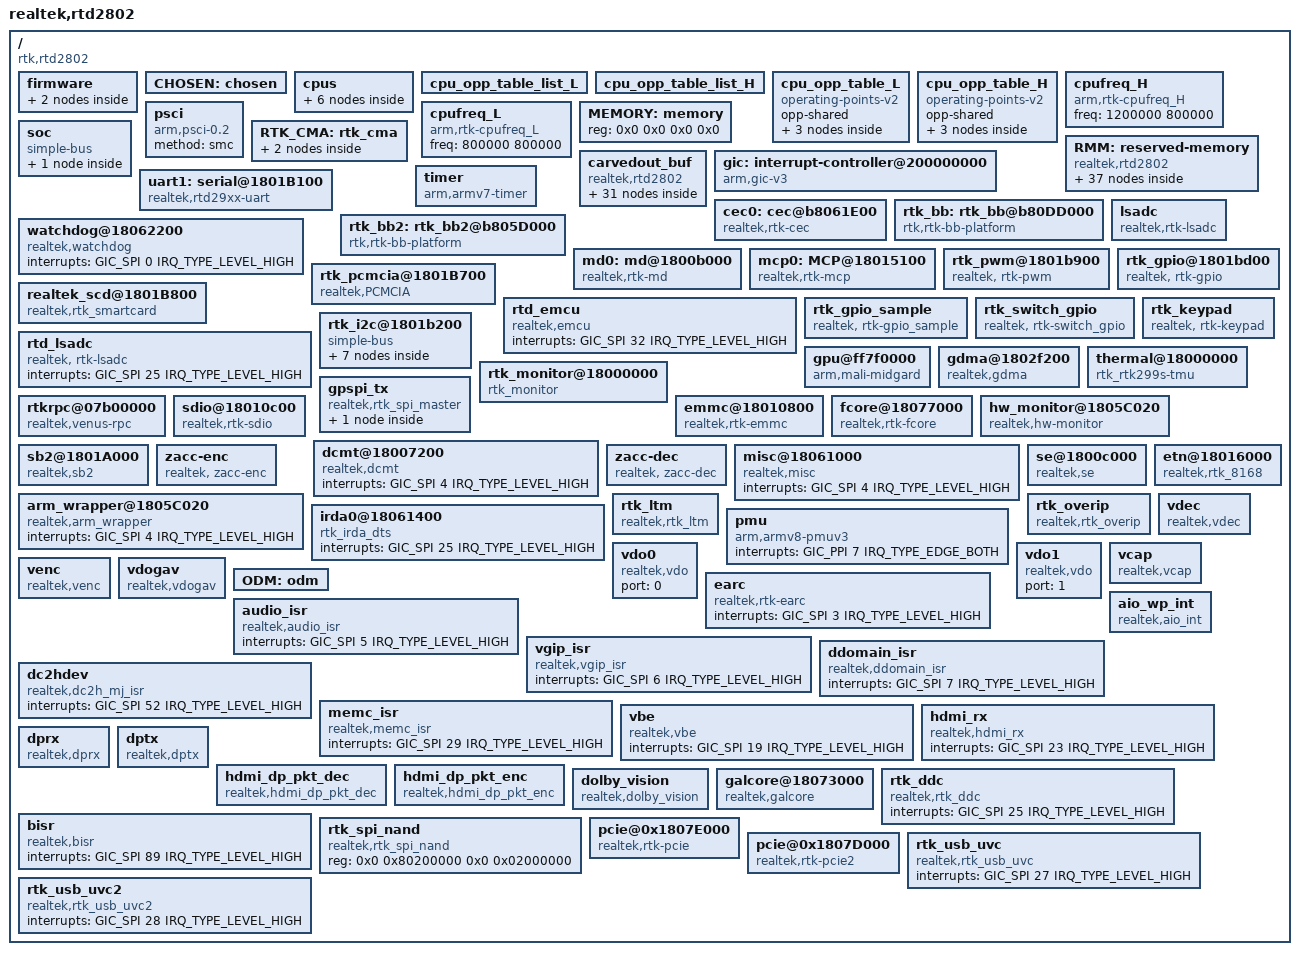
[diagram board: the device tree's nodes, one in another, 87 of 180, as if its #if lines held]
/*
 * rtd2802 device tree source
 *
*/

#include <dt-bindings/interrupt-controller/irq.h>
#include <dt-bindings/interrupt-controller/arm-gic.h>

#include <rtk-dt-binding_chip/rtk_kdriver/rmm/rmm_carvedout.h>
#include <rtk-dt-binding_linux/generated/autoconf.h>
#include <rtk-dt-binding_linux/generated/uapi/linux/version.h>

/dts-v1/;
/include/ "skeleton.dtsi"
#include "rtk_usb_2802.dtsi"
/include/ "rtd2802_otp_table.dtsi"

#define _KB_ 1024
#define _MB_ 1024*1024

/* define cma1 from end to specified size ahead, and boottime borrowed regions */
#define _CMA_LO_SIZE_       ( 32 * _MB_)
#define _CMA_LO_END_        (0x07000000)
#define _CMA_LO_START_      (_CMA_LO_END_ - _CMA_LO_SIZE_)  // cma1 region

#ifdef CONFIG_REALTEK_MEMORY_MANAGEMENT_MODULE
/* for legacy reclaim & last it takes 64+8MB, but referring bootcode it takes 39+N (N for boot logo)
    the boot logo reserved-memory which will be reclaimed should starts from _CMA_LKOGO_ANIM_,
    enough for raw/jpeg logo, no overlap during kernel boot and before android logo */
#define _CMA_LOGO_ANIM_     (0x03800000 + 0   *_MB_)        // anim
#define _CMA_LOGO_PIC_      (0x03800000 + 64  *_MB_)        // pic
#else
#define _CMA_LOGO_ANIM_     (_CMA_LO_START_ + 0   *_MB_)    // anim
#define _CMA_LOGO_PIC_      (_CMA_LO_START_ + 64  *_MB_)    // pic
#endif


/ {
	model = "realtek,rtd2802";
	compatible = "rtk,rtd2802";
	interrupt-parent = <&gic>;
	#address-cells = <2>;
	#size-cells = <2>;

	firmware {
		android {
			compatible = "android,firmware";
			hardware = "rtd2802";
		};
	};

	CHOSEN: chosen {
#if defined(CONFIG_GKI_HACKS_TO_FIX) && defined(CONFIG_RTK_KDRV_SERIAL_8250_MODULE)
		bootargs = "earlycon cgroup.memory=nokmem firmware_class.path=/vendor/firmware androidboot.console=ttyRTK1 console=ttyRTK1,115200";
#else
		bootargs = "earlycon cgroup.memory=nokmem firmware_class.path=/vendor/firmware";
#endif
		stdout-path = &uart1;
	};

	cpus {
		#address-cells = <0x1>;
		#size-cells = <0>;

		cpu-map {
			cluster0: cluster0 {
				#cooling-cells = <2>; /* min followed by max */

				core0 {
					cpu = <&A73_0>;
				};
				core1 {
					cpu = <&A73_1>;
				};
			};
		};

		A73_0: cpu@0 {
			compatible = "arm,cortex-a73","arm,armv8";
			reg = <0x0>;
			device_type = "cpu";
			enable-method = "psci";
			clock-names = "vlittle";
			operating-points-v2 = <&cpu_opp_table_L>;
			capacity-dmips-mhz = <729>;
			dynamic-power-coefficient = <512>;
		};
		A73_1: cpu@1 {
			compatible = "arm,cortex-a73","arm,armv8";
			reg = <0x1>;
			device_type = "cpu";
			enable-method = "psci";
			clock-names = "vlittle";
			operating-points-v2 = <&cpu_opp_table_L>;
			capacity-dmips-mhz = <729>;
			dynamic-power-coefficient = <512>;
		};
	};

	cpu_opp_table_list_L {
		operating-points-0 = <&cpu_opp_table_L>;
		operating-points-1 = <&cpu_opp_table_L>;
	};

	cpu_opp_table_list_H {
		operating-points-0 = <&cpu_opp_table_H>;
		operating-points-1 = <&cpu_opp_table_H>;
	};

	cpu_opp_table_L: cpu_opp_table_L {
		compatible = "operating-points-v2";
		opp-shared;

		opp-1 {
			opp-hz = /bits/ 64 <799000000>;
			opp-microvolt = <890000>;
			opp-level = <1>;
		};
		opp-2 {
			opp-hz = /bits/ 64 <800000000>;
			opp-microvolt = <890000>;
			opp-level = <1>;
		};
		opp-3 {
			opp-hz = /bits/ 64 <880000000>;
			opp-microvolt = <890000>;
			opp-level = <1>;
		};
	};

	cpu_opp_table_H: cpu_opp_table_H {
		compatible = "operating-points-v2";
		opp-shared;

		opp-1 {
			opp-hz = /bits/ 64 <800000000>;
			opp-microvolt = <890000>;
			opp-level = <1>;
		};
		opp-2 {
			opp-hz = /bits/ 64 <1200000000>;
			opp-microvolt = <890000>;
			opp-level = <1>;
		};
		opp-3 {
			opp-hz = /bits/ 64 <1320000000>;
			opp-microvolt = <890000>;
			opp-level = <1>;
		};
	};

	cpufreq_H {
		compatible = "arm,rtk-cpufreq_H";
		freq = <1200000 800000>;
	};

	cpufreq_L {
		compatible = "arm,rtk-cpufreq_L";
		freq = <800000 800000>;
	};

	psci {
		compatible  = "arm,psci-0.2";
		method = "smc";
	};

	MEMORY:memory {
		device_type = "memory";
		reg = <0x0 0x0 0x0 0x0>;
	};

	RMM: reserved-memory {
		#address-cells = <2>;
		#size-cells = <2>;
		ranges;

		//! Default REF platform memory layout dts
		//!  there will be other concatenated dtb and overlay dto for different board variants
		compatible = "realtek,rtd2802";

		boot: boot_memory {                 reg = <0x0 0x00000000 0x0 (1536 *_KB_)>;
		};

		dmem: dmem_memory {                 reg = <0x0 0x10000000 0x0 (0    *_MB_)>;
			status = "disabled";
			/* BAN_NORMAL if size */
		};

		comem: comem_memory {               reg = <0x0 0x10000000 0x0 (0    *_MB_)>;
			status = "disabled";
		};

		audio: audio_memory {               reg = <0x0 0x14000000 0x0 (0   *_MB_)>;
			no-map;
			status = "disabled";
		};

		demod: demod_memory {               reg = <0x0 0x15400000 0x0 (0    *_MB_)>;
			/* BAN_NOT_USED */
			status = "disabled";
		};

		kboot: kboot_memory {               reg = <0x0 0x15f00000 0x0 (0    *_MB_)>;
			status = "disabled"; // it's 0 at rmm.c
		};

		kcpu: kcpu_memory {                 reg = <0x0 0x07a80000 0x0 (512   *_KB_)>;
			no-map;
			/* BAN_NOT_USED if ! OPTEE */
		};

		gic_mem: gic_mem {                  reg = <0x0 0x17c00000 0x0 (0    *_MB_)>; // HW FIXED
			no-map;
			status = "disabled";
		};

		rbus: rbus_memory {                 reg = <0x0 0x18000000 0x0 (2    *_MB_)>; // HW FIXED
			no-map;
		};


		wov: wov_memory {                        reg = <0x0 0x1a500000 0x0 (0    *_MB_)>;
			status = "disabled";
		};

		emcu: emcu_memory {                       reg = <0x0 0x07180000 0x0 (3    *_MB_)>;
			no-map;
		};

		vcpu: vcpu_memory {                 reg = <0x0 0x07480000 0x0 (6    *_MB_)>;
			no-map;
		};

		rpc: rpc_memory {                   reg = <0x0 0x07b00000 0x0 (1020  *_KB_)>;
		};

		acpu: acpu_memory {                 reg = <0x0 0x1b200000 0x0 (0   *_MB_)>;
			no-map;
			status = "disabled";
		};

		/*
		 * The maximum reserved space for logbuf
		 *  bootloader can specify smaller size (e.g. 512K) and update loaded fdt to free unused.
		 */
		logbuf: logbuf_memory {             reg = <0x0 0x07c00000 0x0 (4    *_MB_)>;

			/* rtdlog_get_buffer_size() should be early in kernel */
		};

		rom: rom_memory {                   reg = <0x0 0xffff0000 0x0 0x00010000>;
		};

		pstore: pstore_memory {             reg = <0x0 0x1fd00000 0x0 (0   *_KB_)>;
			status = "disabled";
		};

		irtbl: irtbl_memory {               reg = <0x0 0x07bff000 0x0 (4    *_KB_)>;
		};

		ddr_bd1: ddr_bd1_memory {           reg = <0x0 0x0 0x0 0x0>;
			status = "disabled";
			no-map;
			/* BAN_NOT_USED if ddr_swap */
		};
		ddr_bd2: ddr_bd2_memory {           reg = <0x0 0x0 0x0 0x0>;
			status = "disabled";
			/* BAN_NOT_USED if size */
		};

		// CARVEDOUT_VDEC_VBM
		// (paired with ...CARVEOUT_HEAP_CHUNK_SIZE)
		vdec_vbm: vdec-vbm_memory {         reg = <0x0 0x0 0x0 0x0>;
			no-map; // VDEC_VBM(remove), CMA_VBM(reserve)
			status = "disabled";
		};

		// CARVEDOUT_CMA_VBM
		// (paired with VBM_HEAP_...CHUNK_SIZE)
		vbm: cma-vbm_memory {               reg = <0x0 0x20000000 0x0 (224  *_MB_)>;
			/* no-map; */ // VDEC_VBM(remove), CMA_VBM(reserve)

			// CARVEDOUT_CMA_VBM
			//! 1. should be shared-dma_pool for native reserve-memory to reserve it for dma/cma
			//! 2. 'xxxx'_memory should be paired with rtkcma_list[ ] name in auth
			compatible = "shared-dma-pool"; // CMA_VBM(reserve)
			reusable;
			status = "disabled";
		};

		scaler_memc: scaler_memc {          reg = <0x0 0x2e000000 0x0 (0   *_MB_)>;
			no-map;
			status = "disabled";
		};

		scaler_mdomain: scaler_mdomain {    reg = <0x0 0x33c00000 0x0 (0   *_MB_)>;
			no-map;
			status = "disabled";
		};

		scaler_dinr: scaler_dinr {          reg = <0x0 0x35800000 0x0 (0   *_MB_)>;
			no-map;
			status = "disabled";
		};

		scaler_vip: scaler_vip {            reg = <0x0 0x36200000 0x0 (0    *_MB_)>;
			no-map;
			status = "disabled";
		};

		scaler_od: scaler_od {              reg = <0x0 0x36500000 0x0 (0    *_MB_)>;
			no-map;
			status = "disabled";
		};

		scaler_nn: scaler_nn {              reg = <0x0 0x36e00000 0x0 (0    *_MB_)>;
			no-map;
			status = "disabled";
		};
		scaler_align: _scaler_align {       reg = <0x0 0x36f00000 0x0 (0    *_MB_)>; // ??? scaler reserve 4MB-aligned ???
		};

		tp: tp_memory {                     reg = <0x0 0x37000000 0x0 (0   *_MB_)>;
			//no-map;
			status = "disabled";
		};

		// CARVEDOUT_GPU_RESERVED


		// CARVEDOUT_VDEC_RINGBUF
		svp: svp_memory {                   reg = <0x0 0x3f000000 0x0 (0   *_MB_)>;
			no-map;
			status = "disabled";
		};

		// CARVEDOUT_CMA_LOW

		cma1: cma1_memory {                 reg = <0x0 _CMA_LO_START_ 0x0 _CMA_LO_SIZE_>;
			compatible = "shared-dma-pool";
			reusable;
#ifndef CONFIG_REALTEK_MEMORY_MANAGEMENT_MODULE
			linux,cma-default;
#endif
		};

		// CARVEDOUT_CMA_HIGH
		// CARVEDOUT_CMA_GPU_4K
		/*
		 * carvedout_buf_query[ CARVEDOUT_GPU_RESERVED ]
		 *  (layout_idx == MM_LAYOUT_DEFAULT)  CMA_HIGHMEM_TV_4K; //688MB
		 *  (layout_idx == MM_LAYOUT_DIAS_2GB)  CMA_HIGHMEM_DIAS_2GB; //704MB
		 *
		 *  tp_memory end 0x37000000
		 *  dram      end 0x80000000 : 0x20000000+0x60000000
		 *
		 *  0x37000000 + 128MB(ZRAM_RESERVED_SIZE) + 688MB(CMA_HIGHMEM_TV_4K)
		 *  = 0x37000000 + 0x08000000 + 0x2b000000 = 0x6a000000
		 *
		 *  0x80000000 - 0x6a000000 = 0x16000000 = 352*_MB_
		 */

		/*
		 * if carvedout start < CARVEDOUT_LIMIT(512MB), then NO cma2
		 */

		/*
		 * if UI_4K, CMA_GPU_4K use an exclusive region from original CMA2
		 */

		cma_ui4k: cma-ui4k_memory {         reg = <0x0 0x0 0x0 0x0>;
			compatible = "shared-dma-pool";
			reusable;
			status = "disabled";
		};
		cma2: cma2_memory {                 reg = <0x0 0x0c000000 0x0 ( 64 *_MB_)>;
			compatible = "shared-dma-pool";
			reusable;
		};

		// CARVEDOUT_CMA_3
		cma3_memory {                       reg = <0x0 0x0c000000 0x0 ( 0   *_MB_)>;
			compatible = "shared-dma-pool";
			reusable;
			status = "disabled";
		};
		
		// CARVEDOUT_CMA_LOW_LIMIT
		// CARVEDOUT_CMA_BW

		spi_iomem {                         reg = <0x0 0x80200000 0x0 0x02000000>; // HW FIXED
			no-map;
		};

		// for those less than 4G, prevent them touching 4G addr space
		// especially for those like fixed 2G rescue, or hacked 2G
		reserved_4g {                       reg = <0x0 0xC0000000 0x0 0x40000000>;
			no-map;
		};

	};


	//[TODO] for GKI, cma1 region is reserved in the very beginning but will be returned back to buddy after init.
	//         reserve_dvr_memory() may not be loaded and reserves it in time to avoid other driver access.
	//         may need to be more careful on module loading order.

	/*
	 * CMA param
	 */
	RTK_CMA: rtk_cma {
		#address-cells = <2>;
		#size-cells = <2>;

		reclaim_memory {                    reg = <0x0 _CMA_LOGO_ANIM_ 0x0 (64   *_MB_)>;
		};

		last_image_memory {                 reg = <0x0 _CMA_LOGO_PIC_  0x0 (8    *_MB_)>;
		};
	};

	carvedout_buf {
		#address-cells = <1>;
		#size-cells = <0>;

		compatible = "realtek,rtd2802";
		memory-region = <&MEMORY>;

		/* carvedout idx, refer rmm.h */

		bufnum = < CARVEDOUT_NUM >;

		@CARVEDOUT_BOOTCODE {
			memory-region = "boot_memory";
			reg = < CARVEDOUT_BOOTCODE >;
		};
		@CARVEDOUT_DEMOD {
			memory-region = "demod_memory";
			reg = < CARVEDOUT_DEMOD >;
		};
		@CARVEDOUT_AV_DMEM {
			memory-region = "dmem_memory";
			reg = < CARVEDOUT_AV_DMEM >;
		};
//		@CARVEDOUT_VDEC_COMEM {
//			memory-region = "comem_memory";
//			reg = < CARVEDOUT_VDEC_COMEM >;
//		};
		@CARVEDOUT_AUDIO {
			memory-region = "audio_memory";
			reg = < CARVEDOUT_AUDIO >;
		};
		@CARVEDOUT_K_BOOT {
			memory-region = "kboot_memory";
			reg = < CARVEDOUT_K_BOOT >;
		};
		@CARVEDOUT_K_OS {
			memory-region = "kcpu_memory";
			reg = < CARVEDOUT_K_OS >;
		};
		@CARVEDOUT_MAP_GIC {
			memory-region = "gic_mem";
			reg = < CARVEDOUT_MAP_GIC >;
		};
		@CARVEDOUT_MAP_RBUS {
			memory-region = "rbus_memory";
			reg = < CARVEDOUT_MAP_RBUS >;
		};
		//CARVEDOUT_GPU_FW {
		//};
		@CARVEDOUT_V_OS {
			memory-region = "vcpu_memory";
			reg = < CARVEDOUT_V_OS >;
		};
		@CARVEDOUT_MAP_RPC {
			memory-region = "rpc_memory";
			reg = < CARVEDOUT_MAP_RPC >;
		};
		@CARVEDOUT_A_OS {
			memory-region = "acpu_memory";
			reg = < CARVEDOUT_A_OS >;
		};
		@CARVEDOUT_LOGBUF {
			memory-region = "logbuf_memory";
			reg = < CARVEDOUT_LOGBUF >;
		};
		@CARVEDOUT_ROMCODE {
			memory-region = "rom_memory";
			reg = < CARVEDOUT_ROMCODE >;
		};
		@CARVEDOUT_RAMOOPS {
			memory-region = "pstore_memory";
			reg = < CARVEDOUT_RAMOOPS >;
		};
		@CARVEDOUT_IR_TABLE {
			memory-region = "irtbl_memory";
			reg = < CARVEDOUT_IR_TABLE >;
		};

		@CARVEDOUT_DDR_BOUNDARY {
			memory-region = "ddr_bd1_memory";
			reg = < CARVEDOUT_DDR_BOUNDARY >;
		};
		@CARVEDOUT_DDR_BOUNDARY_2 {
			memory-region = "ddr_bd2_memory";
			reg = < CARVEDOUT_DDR_BOUNDARY_2 >;
		};

		@CARVEDOUT_VDEC_RINGBUF {
			memory-region = "svp_memory";
			reg = < CARVEDOUT_VDEC_RINGBUF >;
		};

		//CARVEDOUT_SCALER

		@CARVEDOUT_SCALER_MEMC {
			memory-region = "scaler_memc";
			reg = < CARVEDOUT_SCALER_MEMC >;
		};
		@CARVEDOUT_SCALER_MDOMAIN {
			memory-region = "scaler_mdomain";
			reg = < CARVEDOUT_SCALER_MDOMAIN >;
		};
		@CARVEDOUT_SCALER_DI_NR {
			memory-region = "scaler_dinr";
			reg = < CARVEDOUT_SCALER_DI_NR >;
		};
		@CARVEDOUT_SCALER_NN {
			memory-region = "scaler_nn";
			reg = < CARVEDOUT_SCALER_NN >;
		};
		@CARVEDOUT_SCALER_VIP {
			memory-region = "scaler_vip";
			reg = < CARVEDOUT_SCALER_VIP >;
		};
		@CARVEDOUT_SCALER_OD {
			memory-region = "scaler_od";
			reg = < CARVEDOUT_SCALER_OD >;
		};

		@CARVEDOUT_VDEC_VBM {
			memory-region = "vdec-vbm_memory";
			reg = < CARVEDOUT_VDEC_VBM>;
		};

		@CARVEDOUT_CMA_VBM {
			memory-region = "cma-vbm_memory";
			reg = < CARVEDOUT_CMA_VBM >;
		};

			@CARVEDOUT_TP {
			memory-region = "tp_memory";
			reg = < CARVEDOUT_TP >;
		};

		@CARVEDOUT_CMA_LOW {
			memory-region = "cma1_memory";
			reg = < CARVEDOUT_CMA_LOW >;
		};

		@CARVEDOUT_CMA_HIGH {
			memory-region = "cma2_memory";
			reg = < CARVEDOUT_CMA_HIGH >;
		};

		@CARVEDOUT_CMA_GPU_4K {
			memory-region = "cma-ui4k_memory";
			reg = < CARVEDOUT_CMA_GPU_4K >;
		};

		@CARVEDOUT_CMA_3 {
			memory-region = "cma3_memory";
			reg = < CARVEDOUT_CMA_3 >;
		};
	};


	firmware {
		optee {
			compatible = "linaro,optee-tz";
			method = "smc";
		};
	};

	gic:interrupt-controller@200000000 {
		compatible = "arm,gic-v3";
		#interrupt-cells = <0x3>;
		#address-cells = <0x2>;
		#size-cells = <0x2>;
		interrupt-controller;
		redistributor-stride = <0x0 0x20000>;
		#redistributor-regions = <1>;
		reg = <0x2 0x00000000 0x0 0x10000>,	   // GICD
				<0x2 0x00040000 0x0 0x200000>;	  // GICR
		interrupts = <GIC_PPI 9 (GIC_CPU_MASK_SIMPLE(4) | IRQ_TYPE_LEVEL_LOW)>;
	};

	soc {
		compatible = "simple-bus";
		#address-cells = <1>;
		#size-cells = <1>;
		ranges = <0 0 0 0xffffffff>; // 32bit addressing

		reg_bus: common@18000000 {
			compatible = "realtek,common";
			#address-cells = <1>;
			#size-cells = <1>;
			reg = <0x18000000 0x200000>;
			ranges = <0 0x18000000 0x200000>;
#if 0
			my_driver: syscon@0 {
				compatible = "syscon", "simple-mfd";
			};
#endif
		};
	};

	timer {
		compatible = "arm,armv7-timer";
		interrupts =
			<GIC_PPI 13 (GIC_CPU_MASK_SIMPLE(4) | IRQ_TYPE_LEVEL_LOW)>,
			<GIC_PPI 14 (GIC_CPU_MASK_SIMPLE(4) | IRQ_TYPE_LEVEL_LOW)>,
			<GIC_PPI 11 (GIC_CPU_MASK_SIMPLE(4) | IRQ_TYPE_LEVEL_LOW)>,
			<GIC_PPI 10 (GIC_CPU_MASK_SIMPLE(4) | IRQ_TYPE_LEVEL_LOW)>;
		clock-frequency = <27000000>;
		always-on = "true";
		arm,no-tick-in-suspend;
	};

	uart1: serial@1801B100 {
		#address-cells = <2>;
		size-cells = <2>;
		compatible = "realtek,rtd29xx-uart", "ns16550";
		reg-shift = <2>;
		reg-io-width = <4>;
		reg = <0x00000000 0x1801B100 0x00000000 0x1000>;
		interrupts = <GIC_SPI 19 IRQ_TYPE_LEVEL_HIGH>,
					<GIC_SPI 17 IRQ_TYPE_LEVEL_HIGH>,
					<GIC_SPI 17 IRQ_TYPE_LEVEL_HIGH>,
					<GIC_SPI 17 IRQ_TYPE_LEVEL_HIGH>;
	};

	cec0: cec@b8061E00 {
		compatible = "realtek,rtk-cec";
		reg = <0x00000000 0x18061E00 0x00000000 0x1000>;
		interrupts = <GIC_SPI 25 IRQ_TYPE_LEVEL_HIGH>;
	};

	rtk_bb: rtk_bb@b80DD000 {
		compatible = "rtk,rtk-bb-platform";
		reg = <0x00000000 0x180DD000 0x00000000 0x1000>;
		interrupts = <GIC_SPI 46 IRQ_TYPE_LEVEL_HIGH>;
		id = <0x0>;
	};

	rtk_bb2: rtk_bb2@b805D000 {
		compatible = "rtk,rtk-bb-platform";
		reg = <0x00000000 0x1807A000 0x00000000 0x1000>;
		interrupts = <GIC_SPI 46 IRQ_TYPE_LEVEL_HIGH>;
		id = <0x1>;
	};

	lsadc {
		compatible = "realtek,rtk-lsadc";
		reg = <0x00000000 0x18061500 0x00000000 0x100>;
		interrupts = <GIC_SPI 25 IRQ_TYPE_LEVEL_HIGH>;
	};

	watchdog@18062200 {
		compatible = "realtek,watchdog";
		interrupts = <GIC_SPI 0 IRQ_TYPE_LEVEL_HIGH>;
	};

	md0:md@1800b000 {
		compatible = "realtek,rtk-md";
		reg = <0x00000000 0x1800b000 0x00000000 0x230>;
		interrupts = <GIC_SPI 13 IRQ_TYPE_LEVEL_HIGH>;
	};

	mcp0:MCP@18015100 {
		compatible = "realtek,rtk-mcp";
		reg = <0x00000000 0x18015100 0x00000000 0x1000>;
		interrupts = <GIC_SPI 12 IRQ_TYPE_LEVEL_HIGH>;
	};


	rtk_pwm@1801b900 {
		compatible = "realtek, rtk-pwm";
		reg = <0x00000000 0x1801b900 0x00000000 0x194>, //misc pwm
				<0x00000000 0x18061280 0x00000000 0x34>;  //iso pwm
		interrupts = <GIC_SPI 37 IRQ_TYPE_LEVEL_HIGH>;  //misc pwm int
	};

	rtk_pcmcia@1801B700 {
		compatible = "realtek,PCMCIA";
		reg = <0x00000000 0x1801B700 0x00000000 0x24>;
		interrupts = <GIC_SPI 19 IRQ_TYPE_LEVEL_HIGH>;//IRQ_TYPE_EDGE_BOTH
	};

	realtek_scd@1801B800 {
		compatible = "realtek,rtk_smartcard";
		reg = <0x00000000 0x1801B800 0x00000000 0x7C>;
		interrupts = <GIC_SPI 19 IRQ_TYPE_LEVEL_HIGH>;//IRQ_TYPE_EDGE_BOTH
	};

	rtd_emcu {
		compatible = "realtek,emcu";
		interrupts = <GIC_SPI 32 IRQ_TYPE_LEVEL_HIGH>;
	};

	rtk_gpio@1801bd00 {
		compatible = "realtek, rtk-gpio";
		reg = <0x00000000 0x1801bd00 0x00000000 0xc0>, //misc gpio
				<0x00000000 0x18061100 0x00000000 0x4c>;
		interrupts = <GIC_SPI 33 IRQ_TYPE_LEVEL_HIGH>,  //misc gpio int*/
				<GIC_SPI 25 IRQ_TYPE_LEVEL_HIGH>;  //iso gpio int*/
	};

	rtk_gpio_sample {
		compatible = "realtek, rtk-gpio_sample";
	};

	rtk_switch_gpio {
		compatible = "realtek, rtk-switch_gpio";
	};

	rtk_keypad {
		compatible = "realtek, rtk-keypad";
	};

	rtd_lsadc {
		compatible = "realtek, rtk-lsadc";
		interrupts = <GIC_SPI 25 IRQ_TYPE_LEVEL_HIGH>;
	};

	rtk_i2c@1801b200 {
		compatible = "simple-bus";
		reg = <0x00000000 0x1801b200 0x00000000 0x3fc>, //misc i2c
				<0x00000000 0x18062500 0x00000000 0x1fc>; //iso i2c
		i2c0{
			compatible = "realtek, rtk-i2c";
			interrupts = <GIC_SPI 25 IRQ_TYPE_LEVEL_HIGH>; //iso misc irq
			pcb_info = <0 0 0 0>;	//logical_id:0, i2c_mode:0.hw_i2c	phy_id, src
						//							1.gpio_i2c sda,	scl
		};
		i2c1{
			compatible = "realtek, rtk-i2c";
			interrupts = <GIC_SPI 19 IRQ_TYPE_LEVEL_HIGH>; //misc irq
			pcb_info = <1 0 1 0>;	//logical_id:1, i2c_mode:0.hw_i2c	phy_id, src
						//							1.gpio_i2c sda,	scl
		};
		i2c2{
			compatible = "realtek, rtk-i2c";
			interrupts = <GIC_SPI 19 IRQ_TYPE_LEVEL_HIGH>; //misc irq
			pcb_info = <2 0 2 0>;	//logical_id2:, i2c_mode:0.hw_i2c	phy_id, src
						//							1.gpio_i2c sda,	scl
		};
		i2c3{
			compatible = "realtek, rtk-i2c";
			interrupts = <GIC_SPI 19 IRQ_TYPE_LEVEL_HIGH>; //misc irq
			pcb_info = <3 0 3 0>;   //logical_id2:, i2c_mode:0.hw_i2c   phy_id, src
						//                          1.gpio_i2c sda, scl
		};
		i2c4{
			compatible = "realtek, rtk-i2c";
			interrupts = <GIC_SPI 19 IRQ_TYPE_LEVEL_HIGH>; //misc irq
			pcb_info = <4 0 4 0>;   //logical_id2:, i2c_mode:0.hw_i2c   phy_id, src
						//                          1.gpio_i2c sda, scl
		};
		i2c5{
			compatible = "realtek, rtk-i2c";
			interrupts = <GIC_SPI 25 IRQ_TYPE_LEVEL_HIGH>; //iso misc irq
			pcb_info = <5 0 5 0>;   //logical_id2:, i2c_mode:0.hw_i2c   phy_id, src
						//                          1.gpio_i2c sda, scl
		};
		i2c6{
			compatible = "realtek, rtk-i2c";
			interrupts = <GIC_SPI 19 IRQ_TYPE_LEVEL_HIGH>; //misc irq
			pcb_info = <6 0 6 0>;   //logical_id2:, i2c_mode:0.hw_i2c   phy_id, src
						//                          1.gpio_i2c sda, scl
		};
	};

	gpu@ff7f0000{
		compatible = "arm,mali-midgard";
		reg = <0x00000000 0xff7f0000 0x00000000 0x4000>;
		interrupts = <GIC_SPI 44 IRQ_TYPE_LEVEL_HIGH>,
						<GIC_SPI 42 IRQ_TYPE_LEVEL_HIGH>,
						<GIC_SPI 14 IRQ_TYPE_LEVEL_HIGH>;
		interrupt-names = "JOB", "MMU", "GPU";
		clock-names = "clk_mali";
	};

	gdma@1802f200 {
		#address-cells = <2>;
		#size-cells = <2>;
		device_type = "osd";
		compatible = "realtek,gdma";
		reg = <0x00000000 0x1802f200 0x00000000 0xe00>;
		interrupts = <GIC_SPI 87 IRQ_TYPE_LEVEL_HIGH>;
	};


	thermal@18000000 {
		compatible = "rtk_rtk299s-tmu";
		reg = <0 0x18000000 0 0x400>;
		interrupts = <GIC_SPI 41 IRQ_TYPE_LEVEL_HIGH>;
		status = "okay";
		throttle = <70 80 120 130>;
	};

	rtk_monitor@18000000 {
		compatible = "rtk_monitor";
		status = "okay";
	};

	gpspi_tx {
		compatible = "realtek,rtk_spi_master";
		reg = <0x0 0x18046080 0x0 0x50>;
		interrupts = <GIC_SPI 30 IRQ_TYPE_LEVEL_HIGH>;
		status = "okay";
		command-count = <0x1>;
		address-count = <0x0>;
		dummy-count = <0x0>;
		spidev@0 {
			compatible = "semtech,sx1301";
			spi-max-frequency = <16000000>;
			reg = <0x0>;
		};
	};

	rtkrpc@07b00000 {
		compatible = "realtek,venus-rpc";
		reg = <0x0 0x07b00000 0x0 0x000ff000>;
		interrupts = <GIC_SPI 3 IRQ_TYPE_LEVEL_HIGH>;
	};

	emmc@18010800 {
		compatible = "realtek,rtk-emmc";
		reg = <0x00000000 0x18010800 0x00000000 0x400>;
		interrupts = <GIC_SPI 18 IRQ_TYPE_LEVEL_HIGH>;
	};

	fcore@18077000 {
		compatible = "realtek,rtk-fcore";
		reg = <0x00000000 0x18077000 0x00000000 0x100>;
		interrupts = <GIC_SPI 53 IRQ_TYPE_LEVEL_HIGH>;
	};

	sdio@18010c00 {
		compatible = "realtek,rtk-sdio";
		reg = <0x00000000 0x18010c00 0x00000000 0x400>;
		interrupts = <GIC_SPI 18 IRQ_TYPE_LEVEL_HIGH>;
		bus-width = <4>;
		max-frequency = <37000000>;
		cap-sd-highspeed;
		cap-mmc-hw-reset;
		broken-cd;
	};

	hw_monitor@1805C020 {
		compatible = "realtek,hw-monitor";
	};

	dcmt@18007200 {
		compatible = "realtek,dcmt";
		interrupts = <GIC_SPI 4 IRQ_TYPE_LEVEL_HIGH>;
	};

	sb2@1801A000 {
		compatible = "realtek,sb2";
		interrupts = <GIC_SPI 4 IRQ_TYPE_LEVEL_HIGH>,
					<GIC_SPI 3 IRQ_TYPE_LEVEL_HIGH>;
		interrupt-names = "SB2_INT",
				"SW_INT";
	};

	zacc-enc{
		compatible = "realtek, zacc-enc";
	};

	zacc-dec{
		compatible = "realtek, zacc-dec";
	};

	misc@18061000 {
		compatible = "realtek,misc";
		interrupts = <GIC_SPI 4 IRQ_TYPE_LEVEL_HIGH>;
	};

	arm_wrapper@1805C020 {
		compatible = "realtek,arm_wrapper";
		interrupts = <GIC_SPI 4 IRQ_TYPE_LEVEL_HIGH>;
	};

	irda0@18061400 {
		compatible = "rtk_irda_dts";
		interrupts = <GIC_SPI 25 IRQ_TYPE_LEVEL_HIGH>;
		//interrupts = < 0 31 0 >;
	};

	se@1800c000 {
		#address-cells = <2>;
		#size-cells = <2>;
		device_type = "2dgraphic";
		compatible = "realtek,se";
		reg = <0x00000000 0x1800c000 0x00000000 0xf00>;
		interrupts = <GIC_SPI 11 IRQ_TYPE_LEVEL_HIGH>;
	};

	etn@18016000 {
                compatible = "realtek,rtk_8168";
                reg = <0x00000000 0x18016000 0x00000000 0x1000>;
                interrupts = <GIC_SPI 20 IRQ_TYPE_LEVEL_HIGH>;
                output-mode = <2>;
                ext_phy_id = <1>;
        };

	rtk_ltm {
		compatible = "realtek,rtk_ltm";
	};

	rtk_overip {
		compatible = "realtek,rtk_overip";
	};

//	clock-controller@18000350 {
//		compatible = "realtek,rtd299s-clock";
//		reg = <0x18000350 0x4b0>;
//		#clock-cells = <1>;
//	};

	pmu {
		compatible = "arm,armv8-pmuv3";
//		interrupts = <GIC_SPI 31 IRQ_TYPE_EDGE_BOTH>;
		interrupts = <GIC_PPI  7 IRQ_TYPE_EDGE_BOTH>; // PPI 23
	};

	vdec {
		compatible = "realtek,vdec";
	};

	vdo0 {
		compatible = "realtek,vdo";
		port = <0>;
	};

	vdo1 {
		compatible = "realtek,vdo";
		port = <1>;
	};

	vcap {
		compatible = "realtek,vcap";
	};

	venc {
		compatible = "realtek,venc";
	};

	vdogav {
		compatible = "realtek,vdogav";
	};

	ODM:odm{
	};

	earc{
		compatible = "realtek,rtk-earc";
		interrupts = <GIC_SPI 3 IRQ_TYPE_LEVEL_HIGH>;
	};

	audio_isr{
		compatible = "realtek,audio_isr";
		interrupts = <GIC_SPI 5 IRQ_TYPE_LEVEL_HIGH>;
	};
	
	aio_wp_int {
		compatible = "realtek,aio_int";
		interrupts = <GIC_SPI 47 IRQ_TYPE_LEVEL_HIGH>,
				<GIC_SPI 48 IRQ_TYPE_LEVEL_HIGH>;
		interrupt-names = "AIO_WP_RX_INT","AIO_WP_TX_INT";
	};

	vgip_isr {
		compatible = "realtek,vgip_isr";
		interrupts = <GIC_SPI 6 IRQ_TYPE_LEVEL_HIGH>;
	};

	ddomain_isr {
		compatible = "realtek,ddomain_isr";
		interrupts = <GIC_SPI 7 IRQ_TYPE_LEVEL_HIGH>;
  	};

	dc2hdev {
		compatible = "realtek,dc2h_mj_isr";
		interrupts = <GIC_SPI 52 IRQ_TYPE_LEVEL_HIGH>;
	};

	memc_isr {
		compatible = "realtek,memc_isr";
		interrupts = <GIC_SPI 29 IRQ_TYPE_LEVEL_HIGH>;
	};

	vbe {
		compatible = "realtek,vbe";
		interrupts = <GIC_SPI 19 IRQ_TYPE_LEVEL_HIGH>;
	};

	hdmi_rx {
		compatible = "realtek,hdmi_rx";
		interrupts = <GIC_SPI 23 IRQ_TYPE_LEVEL_HIGH>;
	};

	dprx {
		compatible = "realtek,dprx";
		interrupts = <GIC_SPI 78 IRQ_TYPE_LEVEL_HIGH>,
				<GIC_SPI 80 IRQ_TYPE_LEVEL_HIGH>;
		interrupt-names = "DPRX_MAC", "DPRX_AUX";
	};
	
	dptx {
		compatible = "realtek,dptx";
		interrupts = <GIC_SPI 41 IRQ_TYPE_LEVEL_HIGH>,
				<GIC_SPI 46 IRQ_TYPE_LEVEL_HIGH>;
		interrupt-names = "DPTX_MAC", "DPTX_AUX";
	};

        hdmi_dp_pkt_dec {
                compatible = "realtek,hdmi_dp_pkt_dec";
                interrupts = <GIC_SPI 43 IRQ_TYPE_LEVEL_HIGH>,
                     <GIC_SPI 41 IRQ_TYPE_LEVEL_HIGH>,
                     <GIC_SPI 85 IRQ_TYPE_LEVEL_HIGH>;
                interrupts-names = "HDMI_PKT_DEC", "DP_PKT_DEC", "HDMITX_PRE2";
        };

        hdmi_dp_pkt_enc {
                compatible = "realtek,hdmi_dp_pkt_enc";
        };

	dolby_vision {
		compatible = "realtek,dolby_vision";
		interrupts = <GIC_SPI 3 IRQ_TYPE_LEVEL_HIGH>,
				<GIC_SPI 19 IRQ_TYPE_LEVEL_HIGH>;
		interrupt-names = "SOFTWARE_IRQ", "MISC_IRQ";
	};

	galcore@18073000 {
		compatible = "realtek,galcore";
		reg = <0x00000000 0x18073000 0x00000000 0x2000>;
		interrupts = <GIC_SPI 30 IRQ_TYPE_LEVEL_HIGH>;
	};

	rtk_ddc {
		compatible = "realtek,rtk_ddc";
		interrupts = <GIC_SPI 25 IRQ_TYPE_LEVEL_HIGH>;
	};

	bisr {
		compatible = "realtek,bisr";
		interrupts = <GIC_SPI 89 IRQ_TYPE_LEVEL_HIGH>;
	};

	rtk_spi_nand {
		compatible = "realtek,rtk_spi_nand";
		#address-cells = <2>;
		#size-cells = <2>;
		reg = <0x0 0x80200000 0x0 0x02000000>;
	};

#define REGION2_START    (0xc0000000)    /* start from 15GB, 0x3_C000_0000 */
#define REGION2_LENGTH   (0x01000000)    /* total 16MB for now */
#define DBI2_MAP_START   (REGION2_START)  /* DBI map start as REGION_START, HW fix */
#define CFG2_MAP_START   (REGION2_START+0x1000)    /* CFG map after 4K offset of REGION_START, HW fix */
#define MMIOMAP2_OFFSET  (0x00100000)    /* 1MB align */
#define MMIOMAP2_START   (REGION2_START+MMIOMAP2_OFFSET) /* MMIO map start, 1MB align */
#define MMIO2_MAP_LENG   (REGION2_LENGTH-MMIOMAP2_OFFSET)
	pcie@0x1807E000 {
		compatible = "realtek,rtk-pcie3";
		reg = <0x00000000 0x1807E000 0x00000000 0x00000C00    /* WRAP reg */
			0x00000003 DBI2_MAP_START 0x00000000 0x00001000    /* rbus2AXI for DBI */
			0x00000003 CFG2_MAP_START 0x00000000 0x00001000>;  /* rbus2AXI for XALI0~2(configuration) */

		reg-names = "wrap", "dbi", "config";
		status = "okay";
		#address-cells = <3>;
		#size-cells = <2>;
		device_type = "pci";
		num-lanes = <2>;
		/* num-viewport = <2>; */
		linux,pci-domain = <1>;
		region-start = <REGION2_START>;
		region-length = <REGION2_LENGTH>;
		reg-base = <0xb807e000>;

		interrupts = <GIC_SPI 35 IRQ_TYPE_LEVEL_HIGH>,  /* INx/PME/msic */
					<GIC_SPI 36 IRQ_TYPE_LEVEL_HIGH>;  /* MSI/MSI-X */
		interrupt-names = "intr", "msi";

		#interrupt-cells = <1>;
		interrupt-map-mask = <0 0 0 0>;
		interrupt-map = <0 0 0 0 &gic 0 0 GIC_SPI 35 IRQ_TYPE_LEVEL_HIGH>;

		bus-range = <0x80 0xff>;
		ranges = <0x82000000 0x00000000 MMIOMAP2_START 0x00000003 MMIOMAP2_START 0x00000000 MMIO2_MAP_LENG>;    /* non-prefetchable memory */
	};

	pcie@0x1807E000 {
		compatible = "realtek,rtk-pcie";
		reg = <0x00000000 0x1807E000 0x00000000 0x00000C00    /* WRAP reg */
			0x00000003 DBI2_MAP_START 0x00000000 0x00001000    /* rbus2AXI for DBI */
			0x00000003 CFG2_MAP_START 0x00000000 0x00001000>;  /* rbus2AXI for XALI0~2(configuration) */

		reg-names = "wrap", "dbi", "config";
		status = "okay";
		#address-cells = <3>;
		#size-cells = <2>;
		device_type = "pci";
		num-lanes = <1>;
		/* num-viewport = <2>; */
		linux,pci-domain = <1>;
		region-start = <REGION2_START>;
		region-length = <REGION2_LENGTH>;
		reg-base = <0xb807e000>;

		interrupts = <GIC_SPI 35 IRQ_TYPE_LEVEL_HIGH>,  /* INx/PME/msic */
					<GIC_SPI 36 IRQ_TYPE_LEVEL_HIGH>;  /* MSI/MSI-X */
		interrupt-names = "intr", "msi";

		#interrupt-cells = <1>;
		interrupt-map-mask = <0 0 0 0>;
		interrupt-map = <0 0 0 0 &gic 0 0 GIC_SPI 35 IRQ_TYPE_LEVEL_HIGH>;

		bus-range = <0x80 0xff>;
		//ranges = <0x82000000 0x00000000 MMIOMAP2_START 0x00000003 MMIOMAP2_START 0x00000000 MMIO2_MAP_LENG>;    /* non-prefetchable memory */
		ranges = <0x82000000 0x00000000 0xc0100000 0x00000003 0xc0100000 0x00000000 0x00100000>;    /* non-prefetchable memory */
	};

#define REGION_START    (0x80000000)    /* start from 14GB, 0x3_8000_0000) */
#define REGION_LENGTH   (0x01000000)    /* total 16MB for now */
#define DBI_MAP_START   (REGION_START)  /* DBI map start as REGION_START, HW fix */
#define CFG_MAP_START   (REGION_START+0x1000)    /* CFG map after 4K offset of REGION_START, HW fix */
#define MMIOMAP_OFFSET  (0x00100000)    /* 1MB align */
#define MMIOMAP_START   (REGION_START+MMIOMAP_OFFSET) /* MMIO map start, 1MB align */
#define MMIO_MAP_LENG   (REGION_LENGTH-MMIOMAP_OFFSET)
	pcie@0x1807D000 {
		compatible = "realtek,rtk-pcie2";
		reg = <0x00000000 0x1807D000 0x00000000 0x00000C00    /* WRAP reg */
			0x00000003 DBI_MAP_START 0x00000000 0x00001000    /* rbus2AXI for DBI */
			0x00000003 CFG_MAP_START 0x00000000 0x00001000>;  /* rbus2AXI for XALI0~2(configuration) */

		reg-names = "wrap", "dbi", "config";
		status = "okay";
		#address-cells = <3>;
		#size-cells = <2>;
		device_type = "pci";
		num-lanes = <1>;
		/* num-viewport = <2>; */
		linux,pci-domain = <0>;
		region-start = <REGION_START>;
		region-length = <REGION_LENGTH>;
		reg-base = <0xb807D000>;

		interrupts = <GIC_SPI 35 IRQ_TYPE_LEVEL_HIGH>,  /* INx/PME/msic */
					<GIC_SPI 38 IRQ_TYPE_LEVEL_HIGH>;  /* MSI/MSI-X */
		interrupt-names = "intr", "msi";

		#interrupt-cells = <1>;
		interrupt-map-mask = <0 0 0 0>;
		interrupt-map = <0 0 0 0 &gic 0 0 GIC_SPI 35 IRQ_TYPE_LEVEL_HIGH>;

		bus-range = <0x0 0x7f>;
		ranges = <0x82000000 0x00000000 MMIOMAP_START 0x00000003 MMIOMAP_START 0x00000000 MMIO_MAP_LENG>;    /* non-prefetchable memory */
	};

	rtk_usb_uvc {
		compatible = "realtek,rtk_usb_uvc";
		interrupts = <GIC_SPI 27 IRQ_TYPE_LEVEL_HIGH>;
		interrupt-names = "USB_UVC_IRQ";
	};

	rtk_usb_uvc2 {
		compatible = "realtek,rtk_usb_uvc2";
		interrupts = <GIC_SPI 28 IRQ_TYPE_LEVEL_HIGH>;
		interrupt-names = "USB_UVC2_IRQ";
	};
};


// multiple layouts

#undef LAYOUTNUM
#define LAYOUTNUM	1
#include "rtd2802/rtd2802_0_256m.dtsi"

#undef LAYOUTNUM
#define LAYOUTNUM	2
#include "rtd2802/rtd2802_1_384m.dtsi"

#undef LAYOUTNUM
#define LAYOUTNUM	3
#include "rtd2802/rtd2802_2_1g5.dtsi"

#undef LAYOUTNUM
#define LAYOUTNUM	4
#include "rtd2802/rtd2802_3_2g.dtsi"

#undef LAYOUTNUM
#define LAYOUTNUM	5
#include "rtd2802/rtd2802_4_256m_small_vbm.dtsi"

#undef LAYOUTNUM
#define LAYOUTNUM	6
#include "rtd2802/rtd2802_5_256m_medium_vbm.dtsi"

#undef LAYOUTNUM
#define LAYOUTNUM	7
#include "rtd2802/rtd2802_6_256m_small_cma.dtsi"
